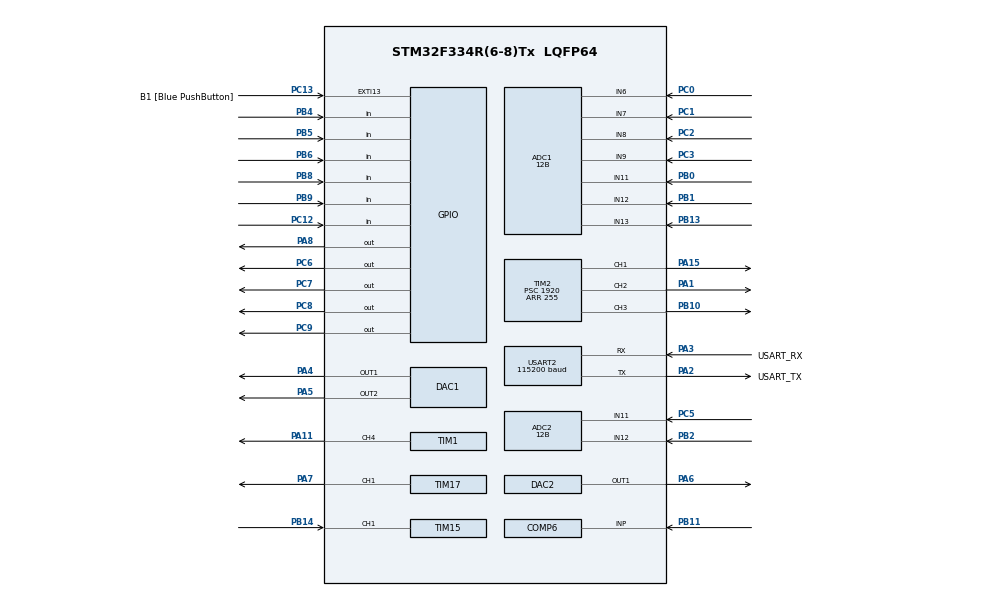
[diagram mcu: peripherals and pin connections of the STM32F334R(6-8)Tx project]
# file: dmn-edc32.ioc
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ADC1.Channel-11\#ChannelRegularConversion=ADC_CHANNEL_6
ADC1.Channel-12\#ChannelRegularConversion=ADC_CHANNEL_7
ADC1.Channel-13\#ChannelRegularConversion=ADC_CHANNEL_8
ADC1.Channel-14\#ChannelRegularConversion=ADC_CHANNEL_9
ADC1.Channel-15\#ChannelRegularConversion=ADC_CHANNEL_11
ADC1.Channel-16\#ChannelRegularConversion=ADC_CHANNEL_12
ADC1.Channel-17\#ChannelRegularConversion=ADC_CHANNEL_13
ADC1.Channel-18\#ChannelRegularConversion=ADC_CHANNEL_TEMPSENSOR
ADC1.ClockPrescaler=ADC_CLOCK_ASYNC_DIV1
ADC1.ContinuousConvMode=ENABLE
ADC1.DMAContinuousRequests=DISABLE
ADC1.DataAlign=ADC_DATAALIGN_RIGHT
ADC1.DiscontinuousConvMode=DISABLE
ADC1.EOCSelection=ADC_EOC_SINGLE_CONV
ADC1.EnableAnalogWatchDog1=false
ADC1.EnableAnalogWatchDog2=false
ADC1.EnableAnalogWatchDog3=false
ADC1.EnableInjectedConversion=ENABLE
ADC1.EnableRegularConversion=ENABLE
ADC1.ExternalTrigConv=ADC_SOFTWARE_START
ADC1.ExternalTrigConvEdge=ADC_EXTERNALTRIGCONVEDGE_NONE
ADC1.InjNumberOfConversion=0
ADC1.LowPowerAutoWait=DISABLE
ADC1.NbrOfConversion=8
ADC1.Offset-11\#ChannelRegularConversion=0
ADC1.Offset-12\#ChannelRegularConversion=0
ADC1.Offset-13\#ChannelRegularConversion=0
ADC1.Offset-14\#ChannelRegularConversion=0
ADC1.Offset-15\#ChannelRegularConversion=0
ADC1.Offset-16\#ChannelRegularConversion=0
ADC1.Offset-17\#ChannelRegularConversion=0
ADC1.Offset-18\#ChannelRegularConversion=0
ADC1.OffsetNumber-11\#ChannelRegularConversion=ADC_OFFSET_NONE
ADC1.OffsetNumber-12\#ChannelRegularConversion=ADC_OFFSET_NONE
ADC1.OffsetNumber-13\#ChannelRegularConversion=ADC_OFFSET_NONE
ADC1.OffsetNumber-14\#ChannelRegularConversion=ADC_OFFSET_NONE
ADC1.OffsetNumber-15\#ChannelRegularConversion=ADC_OFFSET_NONE
ADC1.OffsetNumber-16\#ChannelRegularConversion=ADC_OFFSET_NONE
ADC1.OffsetNumber-17\#ChannelRegularConversion=ADC_OFFSET_NONE
ADC1.OffsetNumber-18\#ChannelRegularConversion=ADC_OFFSET_NONE
ADC1.Overrun=ADC_OVR_DATA_OVERWRITTEN
ADC1.Rank-11\#ChannelRegularConversion=1
ADC1.Rank-12\#ChannelRegularConversion=2
ADC1.Rank-13\#ChannelRegularConversion=3
ADC1.Rank-14\#ChannelRegularConversion=4
ADC1.Rank-15\#ChannelRegularConversion=5
ADC1.Rank-16\#ChannelRegularConversion=6
ADC1.Rank-17\#ChannelRegularConversion=7
ADC1.Rank-18\#ChannelRegularConversion=8
ADC1.Resolution=ADC_RESOLUTION_12B
ADC1.SamplingTime-11\#ChannelRegularConversion=ADC_SAMPLETIME_61CYCLES_5
ADC1.SamplingTime-12\#ChannelRegularConversion=ADC_SAMPLETIME_61CYCLES_5
ADC1.SamplingTime-13\#ChannelRegularConversion=ADC_SAMPLETIME_61CYCLES_5
ADC1.SamplingTime-14\#ChannelRegularConversion=ADC_SAMPLETIME_61CYCLES_5
ADC1.SamplingTime-15\#ChannelRegularConversion=ADC_SAMPLETIME_61CYCLES_5
ADC1.SamplingTime-16\#ChannelRegularConversion=ADC_SAMPLETIME_61CYCLES_5
ADC1.SamplingTime-17\#ChannelRegularConversion=ADC_SAMPLETIME_61CYCLES_5
ADC1.SamplingTime-18\#ChannelRegularConversion=ADC_SAMPLETIME_7CYCLES_5
ADC1.ScanConvMode=ADC_SCAN_ENABLE
ADC1.SubFamily=STM32F334x8
ADC1.master=1
ADC2.Channel-0\#ChannelRegularConversion=ADC_CHANNEL_11
ADC2.ClockPrescaler=ADC_CLOCK_ASYNC_DIV1
ADC2.ContinuousConvMode=ENABLE
ADC2.DMAContinuousRequests=DISABLE
ADC2.DataAlign=ADC_DATAALIGN_RIGHT
ADC2.DiscontinuousConvMode=DISABLE
ADC2.EOCSelection=ADC_EOC_SINGLE_CONV
ADC2.EnableAnalogWatchDog1=false
ADC2.EnableAnalogWatchDog2=false
ADC2.EnableAnalogWatchDog3=false
ADC2.EnableInjectedConversion=ENABLE
ADC2.EnableRegularConversion=ENABLE
ADC2.ExternalTrigConv=ADC_SOFTWARE_START
ADC2.ExternalTrigConvEdge=ADC_EXTERNALTRIGCONVEDGE_NONE
ADC2.InjNumberOfConversion=0
ADC2.LowPowerAutoWait=DISABLE
ADC2.NbrOfConversion=1
ADC2.NbrOfConversionFlag=1
ADC2.Offset-0\#ChannelRegularConversion=0
ADC2.OffsetNumber-0\#ChannelRegularConversion=ADC_OFFSET_NONE
ADC2.Overrun=ADC_OVR_DATA_OVERWRITTEN
ADC2.Rank-0\#ChannelRegularConversion=1
ADC2.Resolution=ADC_RESOLUTION_12B
ADC2.SamplingTime-0\#ChannelRegularConversion=ADC_SAMPLETIME_61CYCLES_5
ADC2.ScanConvMode=ADC_SCAN_DISABLE
ADC2.SingleDiff-0\#ChannelRegularConversion=ADC_DIFFERENTIAL_ENDED
ADC2.SubFamily=STM32F334x8
COMP6.InvertingInput=COMP_INVERTINGINPUT_DAC2_CH1
COMP6.TriggerMode=COMP_TRIGGERMODE_IT_RISING
DAC1.DAC_Trigger=DAC_TRIGGER_T6_TRGO
DAC1.DAC_Trigger2=DAC_TRIGGER_T6_TRGO
Dma.ADC1.4.Direction=DMA_PERIPH_TO_MEMORY
Dma.ADC1.4.Instance=DMA1_Channel1
Dma.ADC1.4.MemDataAlignment=DMA_MDATAALIGN_HALFWORD
Dma.ADC1.4.MemInc=DMA_MINC_ENABLE
Dma.ADC1.4.Mode=DMA_CIRCULAR
Dma.ADC1.4.PeriphDataAlignment=DMA_PDATAALIGN_HALFWORD
Dma.ADC1.4.PeriphInc=DMA_PINC_DISABLE
Dma.ADC1.4.Priority=DMA_PRIORITY_LOW
Dma.ADC2.3.Direction=DMA_PERIPH_TO_MEMORY
Dma.ADC2.3.Instance=DMA1_Channel2
Dma.ADC2.3.MemDataAlignment=DMA_MDATAALIGN_HALFWORD
Dma.ADC2.3.MemInc=DMA_MINC_ENABLE
Dma.ADC2.3.Mode=DMA_NORMAL
Dma.ADC2.3.PeriphDataAlignment=DMA_PDATAALIGN_HALFWORD
Dma.ADC2.3.PeriphInc=DMA_PINC_DISABLE
Dma.ADC2.3.Priority=DMA_PRIORITY_LOW
Dma.DAC1_CH1.1.Direction=DMA_MEMORY_TO_PERIPH
Dma.DAC1_CH1.1.Instance=DMA1_Channel3
Dma.DAC1_CH1.1.MemDataAlignment=DMA_MDATAALIGN_HALFWORD
Dma.DAC1_CH1.1.MemInc=DMA_MINC_ENABLE
Dma.DAC1_CH1.1.Mode=DMA_CIRCULAR
Dma.DAC1_CH1.1.PeriphDataAlignment=DMA_PDATAALIGN_HALFWORD
Dma.DAC1_CH1.1.PeriphInc=DMA_PINC_DISABLE
Dma.DAC1_CH1.1.Priority=DMA_PRIORITY_VERY_HIGH
Dma.DAC1_CH2.2.Direction=DMA_MEMORY_TO_PERIPH
Dma.DAC1_CH2.2.Instance=DMA1_Channel4
Dma.DAC1_CH2.2.MemDataAlignment=DMA_MDATAALIGN_HALFWORD
Dma.DAC1_CH2.2.MemInc=DMA_MINC_ENABLE
Dma.DAC1_CH2.2.Mode=DMA_CIRCULAR
Dma.DAC1_CH2.2.PeriphDataAlignment=DMA_PDATAALIGN_HALFWORD
Dma.DAC1_CH2.2.PeriphInc=DMA_PINC_DISABLE
Dma.DAC1_CH2.2.Priority=DMA_PRIORITY_VERY_HIGH
Dma.Request0=USART2_RX
Dma.Request1=DAC1_CH1
Dma.Request2=DAC1_CH2
Dma.Request3=ADC2
Dma.Request4=ADC1
Dma.USART2_RX.0.Direction=DMA_PERIPH_TO_MEMORY
Dma.USART2_RX.0.Instance=DMA1_Channel6
Dma.USART2_RX.0.MemDataAlignment=DMA_MDATAALIGN_BYTE
Dma.USART2_RX.0.MemInc=DMA_MINC_ENABLE
Dma.USART2_RX.0.Mode=DMA_CIRCULAR
Dma.USART2_RX.0.PeriphDataAlignment=DMA_PDATAALIGN_BYTE
Dma.USART2_RX.0.PeriphInc=DMA_PINC_DISABLE
Dma.USART2_RX.0.Priority=DMA_PRIORITY_LOW
Mcu.Family=STM32F3
Mcu.Name=STM32F334R(6-8)Tx
Mcu.Package=LQFP64
NVIC.ADC1_2_IRQn=true\:0\:0\:false\:false\:true\:true\:true\:true
NVIC.COMP4_6_IRQn=true\:0\:0\:false\:false\:true\:true\:true\:true
NVIC.DMA1_Channel1_IRQn=true\:0\:0\:false\:false\:true\:true\:true\:true
NVIC.DMA1_Channel2_IRQn=true\:0\:0\:false\:false\:true\:true\:true\:true
NVIC.DMA1_Channel3_IRQn=true\:0\:0\:false\:false\:true\:true\:true\:true
NVIC.DMA1_Channel4_IRQn=true\:0\:0\:false\:false\:true\:true\:true\:true
NVIC.DMA1_Channel6_IRQn=true\:0\:0\:false\:false\:true\:true\:true\:true
NVIC.PriorityGroup=NVIC_PRIORITYGROUP_4
NVIC.TIM1_BRK_TIM15_IRQn=true\:0\:0\:false\:false\:true\:true\:true\:true
NVIC.TIM7_DAC2_IRQn=true\:0\:0\:false\:false\:true\:true\:true\:true
NVIC.TimeBase=TIM7_DAC2_IRQn
NVIC.TimeBaseIP=TIM7
NVIC.USART2_IRQn=true\:0\:0\:false\:false\:true\:true\:true\:true
PA1.Signal=S_TIM2_CH2
PA11.Signal=S_TIM1_CH4
PA13.GPIO_Label=TMS
PA13.Signal=SYS_JTMS-SWDIO
PA14.GPIO_Label=TCK
PA14.Signal=SYS_JTCK-SWCLK
PA15.Signal=S_TIM2_CH1_ETR
PA2.GPIO_Label=USART_TX
PA2.Mode=Asynchronous
PA2.Signal=USART2_TX
PA3.GPIO_Label=USART_RX
PA3.Mode=Asynchronous
PA3.Signal=USART2_RX
PA4.Signal=COMP_DAC11_group
PA5.Signal=COMP_DAC12_group
PA6.Signal=COMP_DAC21_group
PA7.Signal=S_TIM17_CH1
PA8.Signal=GPIO_Output
PB0.Mode=IN11-Single-Ended
PB0.Signal=ADC1_IN11
PB1.Mode=IN12-Single-Ended
PB1.Signal=ADC1_IN12
PB10.Signal=S_TIM2_CH3
PB11.GPIO_PuPd=GPIO_NOPULL
PB11.Mode=INP
PB11.Signal=COMP6_INP
PB13.Mode=IN13-Single-Ended
PB13.Signal=ADC1_IN13
PB14.GPIO_PuPd=GPIO_PULLUP
PB14.Signal=S_TIM15_CH1
PB2.Mode=IN11-Differential
PB2.Signal=ADC2_IN12
PB3.GPIO_Label=SWO
PB3.Signal=SYS_JTDO-TRACESWO
PB4.Signal=GPIO_Input
PB5.Signal=GPIO_Input
PB6.Signal=GPIO_Input
PB8.Signal=GPIO_Input
PB9.Signal=GPIO_Input
PC0.Signal=ADCx_IN6
PC1.Signal=ADCx_IN7
PC12.Signal=GPIO_Input
PC13.GPIO_Label=B1 [Blue PushButton]
PC13.GPIO_ModeDefaultEXTI=GPIO_MODE_IT_FALLING
PC13.Signal=GPXTI13
PC14\ /\ OSC32_IN.Signal=RCC_OSC32_IN
PC15\ /\ OSC32_OUT.GPIO_Label=RCC_OSC32_OUT
PC15\ /\ OSC32_OUT.Signal=RCC_OSC32_OUT
PC2.Signal=ADCx_IN8
PC3.Signal=ADCx_IN9
PC5.Mode=IN11-Differential
PC5.Signal=ADC2_IN11
PC6.Signal=GPIO_Output
PC7.Signal=GPIO_Output
PC8.Signal=GPIO_Output
PC9.Signal=GPIO_Output
PF0\ /\ OSC_IN.Signal=RCC_OSC_IN
PF1\ /\ OSC_OUT.Signal=RCC_OSC_OUT
ProjectManager.HeapSize=0x200
ProjectManager.StackSize=0x400
ProjectManager.TargetToolchain=Makefile
RCC.AHBFreq_Value=64000000
RCC.APB1CLKDivider=RCC_HCLK_DIV2
RCC.APB1Freq_Value=32000000
RCC.APB1TimFreq_Value=64000000
RCC.APB2Freq_Value=64000000
RCC.APB2TimFreq_Value=64000000
RCC.CortexFreq_Value=64000000
RCC.FLatency-AdvancedSettings=FLASH_LATENCY_2
RCC.HCLKFreq_Value=64000000
RCC.HSE_VALUE=8000000
RCC.HSI_VALUE=8000000
RCC.LSE_VALUE=32768
RCC.PLLMUL=RCC_PLL_MUL16
RCC.SYSCLKFreq_VALUE=64000000
RCC.SYSCLKSourceVirtual=RCC_SYSCLKSOURCE_PLLCLK
SH.ADCx_IN6.0=ADC1_IN6,IN6-Single-Ended
SH.ADCx_IN7.0=ADC1_IN7,IN7-Single-Ended
SH.ADCx_IN8.0=ADC1_IN8,IN8-Single-Ended
SH.ADCx_IN9.0=ADC1_IN9,IN9-Single-Ended
SH.COMP_DAC11_group.0=DAC1_OUT1,DAC_OUT1
SH.COMP_DAC12_group.0=DAC1_OUT2,DAC_OUT2
SH.COMP_DAC21_group.0=DAC2_OUT1,Switch_Enable_OUT1
SH.S_TIM15_CH1.0=TIM15_CH1,Input_Capture1_from_TI1
SH.S_TIM17_CH1.0=TIM17_CH1,PWM Generation1 CH1
SH.S_TIM1_CH4.0=TIM1_CH4,PWM Generation4 CH4
SH.S_TIM2_CH1_ETR.0=TIM2_CH1,PWM Generation1 CH1
SH.S_TIM2_CH2.0=TIM2_CH2,PWM Generation2 CH2
SH.S_TIM2_CH3.0=TIM2_CH3,PWM Generation3 CH3
TIM1.AutoReloadPreload=TIM_AUTORELOAD_PRELOAD_ENABLE
TIM1.Channel-PWM\ Generation4\ CH4=TIM_CHANNEL_4
TIM1.Period=4095
TIM1.Prescaler=31
TIM15.Channel-Input_Capture1_from_TI1=TIM_CHANNEL_1
TIM15.ICFilter_CH1=15
TIM15.Period=65535
TIM15.Prescaler=244
TIM17.Channel=TIM_CHANNEL_1
TIM17.Period=65535
TIM17.Prescaler=976
TIM17.Pulse=10000
TIM2.Channel-PWM\ Generation1\ CH1=TIM_CHANNEL_1
TIM2.Channel-PWM\ Generation2\ CH2=TIM_CHANNEL_2
TIM2.Channel-PWM\ Generation3\ CH3=TIM_CHANNEL_3
TIM2.Period=255
TIM2.Prescaler=1920
TIM6.Period=49
TIM6.TIM_MasterOutputTrigger=TIM_TRGO_UPDATE
USART2.BaudRate=115200
USART2.VirtualMode-Asynchronous=VM_ASYNC
USART2.WordLength=WORDLENGTH_8B
VP_ADC1_TempSens_Input.Mode=IN-TempSens
VP_COMP6_VS_DAC2OUT1.Mode=INM_DAC2OUT1
VP_SYS_VS_tim7.Mode=TIM7
VP_TIM15_VS_ClockSourceINT.Mode=Internal
VP_TIM17_VS_ClockSourceINT.Mode=Enable_Timer
VP_TIM1_VS_ClockSourceINT.Mode=Internal
VP_TIM2_VS_ClockSourceINT.Mode=Internal
VP_TIM3_VS_ClockSourceINT.Mode=Internal
VP_TIM6_VS_ClockSourceINT.Mode=Enable_Timer
board=NUCLEO-F334R8

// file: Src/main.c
/* USER CODE BEGIN Header */
/**
  ******************************************************************************
  * @file           : main.c
  * @brief          : Main program body
  ******************************************************************************
  * @attention
  *
  * Copyright (c) 2022 STMicroelectronics.
  * All rights reserved.
  *
  * This software is licensed under terms that can be found in the LICENSE file
  * in the root directory of this software component.
  * If no LICENSE file comes with this software, it is provided AS-IS.
  *
  ******************************************************************************
  */
/* USER CODE END Header */
#include "main.h"

/* USER CODE BEGIN Includes */
#include "edc/edcmain.h"

/* USER CODE END Includes */

void SystemClock_Config(void);
static void MX_GPIO_Init(void);
static void MX_DMA_Init(void);
static void MX_USART2_UART_Init(void);
static void MX_DAC1_Init(void);
static void MX_DAC2_Init(void);
static void MX_TIM2_Init(void);
static void MX_COMP6_Init(void);
static void MX_ADC2_Init(void);
static void MX_TIM1_Init(void);
static void MX_ADC1_Init(void);
static void MX_TIM3_Init(void);
static void MX_TIM17_Init(void);
static void MX_TIM15_Init(void);
static void MX_TIM6_Init(void);

int main(void)
{

  /* MCU Configuration--------------------------------------------------------*/

  /* Reset of all peripherals, Initializes the Flash interface and the Systick. */
  HAL_Init();

  /* Configure the system clock */
  SystemClock_Config();

  /* Initialize all configured peripherals */
  MX_GPIO_Init();
  MX_DMA_Init();
  MX_USART2_UART_Init();
  MX_DAC1_Init();
  MX_DAC2_Init();
  MX_TIM2_Init();
  MX_COMP6_Init();
  MX_ADC2_Init();
  MX_TIM1_Init();
  MX_ADC1_Init();
  MX_TIM3_Init();
  MX_TIM17_Init();
  MX_TIM15_Init();
  MX_TIM6_Init();
  /* USER CODE BEGIN 2 */

  edcmain();
  /* USER CODE END 2 */

  /* Infinite loop */
  while (1)
  {

  }
}

void SystemClock_Config(void)
{
  LL_FLASH_SetLatency(LL_FLASH_LATENCY_2);
  while(LL_FLASH_GetLatency()!= LL_FLASH_LATENCY_2)
  {
  }
  LL_RCC_HSI_Enable();

   /* Wait till HSI is ready */
  while(LL_RCC_HSI_IsReady() != 1)
  {

  }
  LL_RCC_HSI_SetCalibTrimming(16);
  LL_RCC_PLL_ConfigDomain_SYS(LL_RCC_PLLSOURCE_HSI_DIV_2, LL_RCC_PLL_MUL_16);
  LL_RCC_PLL_Enable();

   /* Wait till PLL is ready */
  while(LL_RCC_PLL_IsReady() != 1)
  {

  }
  LL_RCC_SetAHBPrescaler(LL_RCC_SYSCLK_DIV_1);
  LL_RCC_SetAPB1Prescaler(LL_RCC_APB1_DIV_2);
  LL_RCC_SetAPB2Prescaler(LL_RCC_APB2_DIV_1);
  LL_RCC_SetSysClkSource(LL_RCC_SYS_CLKSOURCE_PLL);

   /* Wait till System clock is ready */
  while(LL_RCC_GetSysClkSource() != LL_RCC_SYS_CLKSOURCE_STATUS_PLL)
  {

  }
  LL_SetSystemCoreClock(64000000);

   /* Update the time base */
  if (HAL_InitTick (TICK_INT_PRIORITY) != HAL_OK)
  {
    Error_Handler();
  }
  LL_RCC_SetTIMClockSource(LL_RCC_TIM1_CLKSOURCE_PCLK2);
  LL_RCC_SetADCClockSource(LL_RCC_ADC12_CLKSRC_PLL_DIV_1);
}

static void MX_ADC1_Init(void)
{

  LL_ADC_InitTypeDef ADC_InitStruct = {0};
  LL_ADC_REG_InitTypeDef ADC_REG_InitStruct = {0};
  LL_ADC_CommonInitTypeDef ADC_CommonInitStruct = {0};

  LL_GPIO_InitTypeDef GPIO_InitStruct = {0};

  /* Peripheral clock enable */
  LL_AHB1_GRP1_EnableClock(LL_AHB1_GRP1_PERIPH_ADC12);

  LL_AHB1_GRP1_EnableClock(LL_AHB1_GRP1_PERIPH_GPIOC);
  LL_AHB1_GRP1_EnableClock(LL_AHB1_GRP1_PERIPH_GPIOB);
  /**ADC1 GPIO Configuration
  PC0   ------> ADC1_IN6
  PC1   ------> ADC1_IN7
  PC2   ------> ADC1_IN8
  PC3   ------> ADC1_IN9
  PB0   ------> ADC1_IN11
  PB1   ------> ADC1_IN12
  PB13   ------> ADC1_IN13
  */
  GPIO_InitStruct.Pin = LL_GPIO_PIN_0|LL_GPIO_PIN_1|LL_GPIO_PIN_2|LL_GPIO_PIN_3;
  GPIO_InitStruct.Mode = LL_GPIO_MODE_ANALOG;
  GPIO_InitStruct.Pull = LL_GPIO_PULL_NO;
  LL_GPIO_Init(GPIOC, &GPIO_InitStruct);

  GPIO_InitStruct.Pin = LL_GPIO_PIN_0|LL_GPIO_PIN_1|LL_GPIO_PIN_13;
  GPIO_InitStruct.Mode = LL_GPIO_MODE_ANALOG;
  GPIO_InitStruct.Pull = LL_GPIO_PULL_NO;
  LL_GPIO_Init(GPIOB, &GPIO_InitStruct);

  /* ADC1 DMA Init */

  /* ADC1 Init */
  LL_DMA_SetDataTransferDirection(DMA1, LL_DMA_CHANNEL_1, LL_DMA_DIRECTION_PERIPH_TO_MEMORY);

  LL_DMA_SetChannelPriorityLevel(DMA1, LL_DMA_CHANNEL_1, LL_DMA_PRIORITY_LOW);

  LL_DMA_SetMode(DMA1, LL_DMA_CHANNEL_1, LL_DMA_MODE_CIRCULAR);

  LL_DMA_SetPeriphIncMode(DMA1, LL_DMA_CHANNEL_1, LL_DMA_PERIPH_NOINCREMENT);

  LL_DMA_SetMemoryIncMode(DMA1, LL_DMA_CHANNEL_1, LL_DMA_MEMORY_INCREMENT);

  LL_DMA_SetPeriphSize(DMA1, LL_DMA_CHANNEL_1, LL_DMA_PDATAALIGN_HALFWORD);

  LL_DMA_SetMemorySize(DMA1, LL_DMA_CHANNEL_1, LL_DMA_MDATAALIGN_HALFWORD);

  /* ADC1 interrupt Init */
  NVIC_SetPriority(ADC1_2_IRQn, NVIC_EncodePriority(NVIC_GetPriorityGrouping(),0, 0));
  NVIC_EnableIRQ(ADC1_2_IRQn);

  /** Common config
  */
  ADC_InitStruct.Resolution = LL_ADC_RESOLUTION_12B;
  ADC_InitStruct.DataAlignment = LL_ADC_DATA_ALIGN_RIGHT;
  ADC_InitStruct.LowPowerMode = LL_ADC_LP_MODE_NONE;
  LL_ADC_Init(ADC1, &ADC_InitStruct);
  ADC_REG_InitStruct.TriggerSource = LL_ADC_REG_TRIG_SOFTWARE;
  ADC_REG_InitStruct.SequencerLength = LL_ADC_REG_SEQ_SCAN_ENABLE_8RANKS;
  ADC_REG_InitStruct.SequencerDiscont = LL_ADC_REG_SEQ_DISCONT_DISABLE;
  ADC_REG_InitStruct.ContinuousMode = LL_ADC_REG_CONV_CONTINUOUS;
  ADC_REG_InitStruct.DMATransfer = LL_ADC_REG_DMA_TRANSFER_LIMITED;
  ADC_REG_InitStruct.Overrun = LL_ADC_REG_OVR_DATA_OVERWRITTEN;
  LL_ADC_REG_Init(ADC1, &ADC_REG_InitStruct);
  ADC_CommonInitStruct.CommonClock = LL_ADC_CLOCK_ASYNC_DIV1;
  ADC_CommonInitStruct.Multimode = LL_ADC_MULTI_INDEPENDENT;
  LL_ADC_CommonInit(__LL_ADC_COMMON_INSTANCE(ADC1), &ADC_CommonInitStruct);

  /* Enable ADC internal voltage regulator */
  LL_ADC_EnableInternalRegulator(ADC1);
  /* Delay for ADC internal voltage regulator stabilization. */
  /* Compute number of CPU cycles to wait for, from delay in us. */
  /* Note: Variable divided by 2 to compensate partially */
  /* CPU processing cycles (depends on compilation optimization). */
  /* Note: If system core clock frequency is below 200kHz, wait time */
  /* is only a few CPU processing cycles. */
  uint32_t wait_loop_index;
  wait_loop_index = ((LL_ADC_DELAY_INTERNAL_REGUL_STAB_US * (SystemCoreClock / (100000 * 2))) / 10);
  while(wait_loop_index != 0)
  {
    wait_loop_index--;
  }

  /** Configure Regular Channel
  */
  LL_ADC_REG_SetSequencerRanks(ADC1, LL_ADC_REG_RANK_1, LL_ADC_CHANNEL_6);
  LL_ADC_SetChannelSamplingTime(ADC1, LL_ADC_CHANNEL_6, LL_ADC_SAMPLINGTIME_61CYCLES_5);
  LL_ADC_SetChannelSingleDiff(ADC1, LL_ADC_CHANNEL_6, LL_ADC_SINGLE_ENDED);

  /** Configure Regular Channel
  */
  LL_ADC_REG_SetSequencerRanks(ADC1, LL_ADC_REG_RANK_2, LL_ADC_CHANNEL_7);
  LL_ADC_SetChannelSamplingTime(ADC1, LL_ADC_CHANNEL_7, LL_ADC_SAMPLINGTIME_61CYCLES_5);
  LL_ADC_SetChannelSingleDiff(ADC1, LL_ADC_CHANNEL_7, LL_ADC_SINGLE_ENDED);

  /** Configure Regular Channel
  */
  LL_ADC_REG_SetSequencerRanks(ADC1, LL_ADC_REG_RANK_3, LL_ADC_CHANNEL_8);
  LL_ADC_SetChannelSamplingTime(ADC1, LL_ADC_CHANNEL_8, LL_ADC_SAMPLINGTIME_61CYCLES_5);
  LL_ADC_SetChannelSingleDiff(ADC1, LL_ADC_CHANNEL_8, LL_ADC_SINGLE_ENDED);

  /** Configure Regular Channel
  */
  LL_ADC_REG_SetSequencerRanks(ADC1, LL_ADC_REG_RANK_4, LL_ADC_CHANNEL_9);
  LL_ADC_SetChannelSamplingTime(ADC1, LL_ADC_CHANNEL_9, LL_ADC_SAMPLINGTIME_61CYCLES_5);
  LL_ADC_SetChannelSingleDiff(ADC1, LL_ADC_CHANNEL_9, LL_ADC_SINGLE_ENDED);

  /** Configure Regular Channel
  */
  LL_ADC_REG_SetSequencerRanks(ADC1, LL_ADC_REG_RANK_5, LL_ADC_CHANNEL_11);
  LL_ADC_SetChannelSamplingTime(ADC1, LL_ADC_CHANNEL_11, LL_ADC_SAMPLINGTIME_61CYCLES_5);
  LL_ADC_SetChannelSingleDiff(ADC1, LL_ADC_CHANNEL_11, LL_ADC_SINGLE_ENDED);

  /** Configure Regular Channel
  */
  LL_ADC_REG_SetSequencerRanks(ADC1, LL_ADC_REG_RANK_6, LL_ADC_CHANNEL_12);
  LL_ADC_SetChannelSamplingTime(ADC1, LL_ADC_CHANNEL_12, LL_ADC_SAMPLINGTIME_61CYCLES_5);
  LL_ADC_SetChannelSingleDiff(ADC1, LL_ADC_CHANNEL_12, LL_ADC_SINGLE_ENDED);

  /** Configure Regular Channel
  */
  LL_ADC_REG_SetSequencerRanks(ADC1, LL_ADC_REG_RANK_7, LL_ADC_CHANNEL_13);
  LL_ADC_SetChannelSamplingTime(ADC1, LL_ADC_CHANNEL_13, LL_ADC_SAMPLINGTIME_61CYCLES_5);
  LL_ADC_SetChannelSingleDiff(ADC1, LL_ADC_CHANNEL_13, LL_ADC_SINGLE_ENDED);

  /** Configure Regular Channel
  */
  LL_ADC_REG_SetSequencerRanks(ADC1, LL_ADC_REG_RANK_8, LL_ADC_CHANNEL_TEMPSENSOR);
  LL_ADC_SetChannelSamplingTime(ADC1, LL_ADC_CHANNEL_TEMPSENSOR, LL_ADC_SAMPLINGTIME_7CYCLES_5);
  LL_ADC_SetChannelSingleDiff(ADC1, LL_ADC_CHANNEL_TEMPSENSOR, LL_ADC_SINGLE_ENDED);
  LL_ADC_SetCommonPathInternalCh(__LL_ADC_COMMON_INSTANCE(ADC1), LL_ADC_PATH_INTERNAL_TEMPSENSOR);

}

static void MX_ADC2_Init(void)
{

  LL_ADC_InitTypeDef ADC_InitStruct = {0};
  LL_ADC_REG_InitTypeDef ADC_REG_InitStruct = {0};

  LL_GPIO_InitTypeDef GPIO_InitStruct = {0};

  /* Peripheral clock enable */
  LL_AHB1_GRP1_EnableClock(LL_AHB1_GRP1_PERIPH_ADC12);

  LL_AHB1_GRP1_EnableClock(LL_AHB1_GRP1_PERIPH_GPIOC);
  LL_AHB1_GRP1_EnableClock(LL_AHB1_GRP1_PERIPH_GPIOB);
  /**ADC2 GPIO Configuration
  PC5   ------> ADC2_IN11
  PB2   ------> ADC2_IN12
  */
  GPIO_InitStruct.Pin = LL_GPIO_PIN_5;
  GPIO_InitStruct.Mode = LL_GPIO_MODE_ANALOG;
  GPIO_InitStruct.Pull = LL_GPIO_PULL_NO;
  LL_GPIO_Init(GPIOC, &GPIO_InitStruct);

  GPIO_InitStruct.Pin = LL_GPIO_PIN_2;
  GPIO_InitStruct.Mode = LL_GPIO_MODE_ANALOG;
  GPIO_InitStruct.Pull = LL_GPIO_PULL_NO;
  LL_GPIO_Init(GPIOB, &GPIO_InitStruct);

  /* ADC2 DMA Init */

  /* ADC2 Init */
  LL_DMA_SetDataTransferDirection(DMA1, LL_DMA_CHANNEL_2, LL_DMA_DIRECTION_PERIPH_TO_MEMORY);

  LL_DMA_SetChannelPriorityLevel(DMA1, LL_DMA_CHANNEL_2, LL_DMA_PRIORITY_LOW);

  LL_DMA_SetMode(DMA1, LL_DMA_CHANNEL_2, LL_DMA_MODE_NORMAL);

  LL_DMA_SetPeriphIncMode(DMA1, LL_DMA_CHANNEL_2, LL_DMA_PERIPH_NOINCREMENT);

  LL_DMA_SetMemoryIncMode(DMA1, LL_DMA_CHANNEL_2, LL_DMA_MEMORY_INCREMENT);

  LL_DMA_SetPeriphSize(DMA1, LL_DMA_CHANNEL_2, LL_DMA_PDATAALIGN_HALFWORD);

  LL_DMA_SetMemorySize(DMA1, LL_DMA_CHANNEL_2, LL_DMA_MDATAALIGN_HALFWORD);

  /* ADC2 interrupt Init */
  NVIC_SetPriority(ADC1_2_IRQn, NVIC_EncodePriority(NVIC_GetPriorityGrouping(),0, 0));
  NVIC_EnableIRQ(ADC1_2_IRQn);

  /** Common config
  */
  ADC_InitStruct.Resolution = LL_ADC_RESOLUTION_12B;
  ADC_InitStruct.DataAlignment = LL_ADC_DATA_ALIGN_RIGHT;
  ADC_InitStruct.LowPowerMode = LL_ADC_LP_MODE_NONE;
  LL_ADC_Init(ADC2, &ADC_InitStruct);
  ADC_REG_InitStruct.TriggerSource = LL_ADC_REG_TRIG_SOFTWARE;
  ADC_REG_InitStruct.SequencerLength = LL_ADC_REG_SEQ_SCAN_DISABLE;
  ADC_REG_InitStruct.SequencerDiscont = LL_ADC_REG_SEQ_DISCONT_DISABLE;
  ADC_REG_InitStruct.ContinuousMode = LL_ADC_REG_CONV_CONTINUOUS;
  ADC_REG_InitStruct.DMATransfer = LL_ADC_REG_DMA_TRANSFER_LIMITED;
  ADC_REG_InitStruct.Overrun = LL_ADC_REG_OVR_DATA_OVERWRITTEN;
  LL_ADC_REG_Init(ADC2, &ADC_REG_InitStruct);

  /* Enable ADC internal voltage regulator */
  LL_ADC_EnableInternalRegulator(ADC2);
  /* Delay for ADC internal voltage regulator stabilization. */
  /* Compute number of CPU cycles to wait for, from delay in us. */
  /* Note: Variable divided by 2 to compensate partially */
  /* CPU processing cycles (depends on compilation optimization). */
  /* Note: If system core clock frequency is below 200kHz, wait time */
  /* is only a few CPU processing cycles. */
  uint32_t wait_loop_index;
  wait_loop_index = ((LL_ADC_DELAY_INTERNAL_REGUL_STAB_US * (SystemCoreClock / (100000 * 2))) / 10);
  while(wait_loop_index != 0)
  {
    wait_loop_index--;
  }

  /** Configure Regular Channel
  */
  LL_ADC_REG_SetSequencerRanks(ADC2, LL_ADC_REG_RANK_1, LL_ADC_CHANNEL_11);
  LL_ADC_SetChannelSamplingTime(ADC2, LL_ADC_CHANNEL_11, LL_ADC_SAMPLINGTIME_61CYCLES_5);
  LL_ADC_SetChannelSingleDiff(ADC2, LL_ADC_CHANNEL_11, LL_ADC_DIFFERENTIAL_ENDED);

}

static void MX_COMP6_Init(void)
{

  LL_COMP_InitTypeDef COMP_InitStruct = {0};

  LL_GPIO_InitTypeDef GPIO_InitStruct = {0};

  LL_AHB1_GRP1_EnableClock(LL_AHB1_GRP1_PERIPH_GPIOB);
  /**COMP6 GPIO Configuration
  PB11   ------> COMP6_INP
  */
  GPIO_InitStruct.Pin = LL_GPIO_PIN_11;
  GPIO_InitStruct.Mode = LL_GPIO_MODE_ANALOG;
  GPIO_InitStruct.Pull = LL_GPIO_PULL_NO;
  LL_GPIO_Init(GPIOB, &GPIO_InitStruct);

  /* COMP6 interrupt Init */
  NVIC_SetPriority(COMP4_6_IRQn, NVIC_EncodePriority(NVIC_GetPriorityGrouping(),0, 0));
  NVIC_EnableIRQ(COMP4_6_IRQn);

  COMP_InitStruct.InputPlus = LL_COMP_INPUT_PLUS_IO1;
  COMP_InitStruct.InputMinus = LL_COMP_INPUT_MINUS_DAC2_CH1;
  COMP_InitStruct.OutputSelection = LL_COMP_OUTPUT_NONE;
  COMP_InitStruct.OutputPolarity = LL_COMP_OUTPUTPOL_NONINVERTED;
  COMP_InitStruct.OutputBlankingSource = LL_COMP_BLANKINGSRC_NONE;
  LL_COMP_Init(COMP6, &COMP_InitStruct);

}

static void MX_DAC1_Init(void)
{

  LL_DAC_InitTypeDef DAC_InitStruct = {0};

  LL_GPIO_InitTypeDef GPIO_InitStruct = {0};

  /* Peripheral clock enable */
  LL_APB1_GRP1_EnableClock(LL_APB1_GRP1_PERIPH_DAC1);

  LL_AHB1_GRP1_EnableClock(LL_AHB1_GRP1_PERIPH_GPIOA);
  /**DAC1 GPIO Configuration
  PA4   ------> DAC1_OUT1
  PA5   ------> DAC1_OUT2
  */
  GPIO_InitStruct.Pin = LL_GPIO_PIN_4|LL_GPIO_PIN_5;
  GPIO_InitStruct.Mode = LL_GPIO_MODE_ANALOG;
  GPIO_InitStruct.Pull = LL_GPIO_PULL_NO;
  LL_GPIO_Init(GPIOA, &GPIO_InitStruct);

  /* DAC1 DMA Init */

  /* DAC1_CH1 Init */
  LL_DMA_SetDataTransferDirection(DMA1, LL_DMA_CHANNEL_3, LL_DMA_DIRECTION_MEMORY_TO_PERIPH);

  LL_DMA_SetChannelPriorityLevel(DMA1, LL_DMA_CHANNEL_3, LL_DMA_PRIORITY_VERYHIGH);

  LL_DMA_SetMode(DMA1, LL_DMA_CHANNEL_3, LL_DMA_MODE_CIRCULAR);

  LL_DMA_SetPeriphIncMode(DMA1, LL_DMA_CHANNEL_3, LL_DMA_PERIPH_NOINCREMENT);

  LL_DMA_SetMemoryIncMode(DMA1, LL_DMA_CHANNEL_3, LL_DMA_MEMORY_INCREMENT);

  LL_DMA_SetPeriphSize(DMA1, LL_DMA_CHANNEL_3, LL_DMA_PDATAALIGN_HALFWORD);

  LL_DMA_SetMemorySize(DMA1, LL_DMA_CHANNEL_3, LL_DMA_MDATAALIGN_HALFWORD);

  LL_SYSCFG_SetRemapDMA_DAC(LL_SYSCFG_DAC1_CH1_RMP_DMA1_CH3);

  /* DAC1_CH2 Init */
  LL_DMA_SetDataTransferDirection(DMA1, LL_DMA_CHANNEL_4, LL_DMA_DIRECTION_MEMORY_TO_PERIPH);

  LL_DMA_SetChannelPriorityLevel(DMA1, LL_DMA_CHANNEL_4, LL_DMA_PRIORITY_VERYHIGH);

  LL_DMA_SetMode(DMA1, LL_DMA_CHANNEL_4, LL_DMA_MODE_CIRCULAR);

  LL_DMA_SetPeriphIncMode(DMA1, LL_DMA_CHANNEL_4, LL_DMA_PERIPH_NOINCREMENT);

  LL_DMA_SetMemoryIncMode(DMA1, LL_DMA_CHANNEL_4, LL_DMA_MEMORY_INCREMENT);

  LL_DMA_SetPeriphSize(DMA1, LL_DMA_CHANNEL_4, LL_DMA_PDATAALIGN_HALFWORD);

  LL_DMA_SetMemorySize(DMA1, LL_DMA_CHANNEL_4, LL_DMA_MDATAALIGN_HALFWORD);

  LL_SYSCFG_SetRemapDMA_DAC(LL_SYSCFG_DAC1_OUT2_RMP_DMA1_CH4);

  /** DAC channel OUT1 config
  */
  DAC_InitStruct.TriggerSource = LL_DAC_TRIG_EXT_TIM6_TRGO;
  DAC_InitStruct.WaveAutoGeneration = LL_DAC_WAVE_AUTO_GENERATION_NONE;
  DAC_InitStruct.OutputBuffer = LL_DAC_OUTPUT_BUFFER_ENABLE;
  LL_DAC_Init(DAC1, LL_DAC_CHANNEL_1, &DAC_InitStruct);
  LL_DAC_EnableTrigger(DAC1, LL_DAC_CHANNEL_1);

  /** DAC channel OUT2 config
  */
  DAC_InitStruct.OutputBuffer = LL_DAC_OUTPUT_SWITCH_ENABLE;
  LL_DAC_Init(DAC1, LL_DAC_CHANNEL_2, &DAC_InitStruct);
  LL_DAC_EnableTrigger(DAC1, LL_DAC_CHANNEL_2);

}

static void MX_DAC2_Init(void)
{

  LL_DAC_InitTypeDef DAC_InitStruct = {0};

  LL_GPIO_InitTypeDef GPIO_InitStruct = {0};

  /* Peripheral clock enable */
  LL_APB1_GRP1_EnableClock(LL_APB1_GRP1_PERIPH_DAC2);

  LL_AHB1_GRP1_EnableClock(LL_AHB1_GRP1_PERIPH_GPIOA);
  /**DAC2 GPIO Configuration
  PA6   ------> DAC2_OUT1
  */
  GPIO_InitStruct.Pin = LL_GPIO_PIN_6;
  GPIO_InitStruct.Mode = LL_GPIO_MODE_ANALOG;
  GPIO_InitStruct.Pull = LL_GPIO_PULL_NO;
  LL_GPIO_Init(GPIOA, &GPIO_InitStruct);

  /* DAC2 interrupt Init */
  NVIC_SetPriority(TIM7_DAC2_IRQn, NVIC_EncodePriority(NVIC_GetPriorityGrouping(),0, 0));
  NVIC_EnableIRQ(TIM7_DAC2_IRQn);

  /** DAC channel OUT1 config
  */
  DAC_InitStruct.TriggerSource = LL_DAC_TRIG_SOFTWARE;
  DAC_InitStruct.WaveAutoGeneration = LL_DAC_WAVE_AUTO_GENERATION_NONE;
  DAC_InitStruct.OutputBuffer = LL_DAC_OUTPUT_SWITCH_ENABLE;
  LL_DAC_Init(DAC2, LL_DAC_CHANNEL_1, &DAC_InitStruct);
  LL_DAC_DisableTrigger(DAC2, LL_DAC_CHANNEL_1);

}

static void MX_TIM1_Init(void)
{

  LL_TIM_InitTypeDef TIM_InitStruct = {0};
  LL_TIM_OC_InitTypeDef TIM_OC_InitStruct = {0};
  LL_TIM_BDTR_InitTypeDef TIM_BDTRInitStruct = {0};

  LL_GPIO_InitTypeDef GPIO_InitStruct = {0};

  /* Peripheral clock enable */
  LL_APB2_GRP1_EnableClock(LL_APB2_GRP1_PERIPH_TIM1);

  /* TIM1 interrupt Init */
  NVIC_SetPriority(TIM1_BRK_TIM15_IRQn, NVIC_EncodePriority(NVIC_GetPriorityGrouping(),0, 0));
  NVIC_EnableIRQ(TIM1_BRK_TIM15_IRQn);

  TIM_InitStruct.Prescaler = 31;
  TIM_InitStruct.CounterMode = LL_TIM_COUNTERMODE_UP;
  TIM_InitStruct.Autoreload = 4095;
  TIM_InitStruct.ClockDivision = LL_TIM_CLOCKDIVISION_DIV1;
  TIM_InitStruct.RepetitionCounter = 0;
  LL_TIM_Init(TIM1, &TIM_InitStruct);
  LL_TIM_EnableARRPreload(TIM1);
  LL_TIM_SetClockSource(TIM1, LL_TIM_CLOCKSOURCE_INTERNAL);
  LL_TIM_OC_EnablePreload(TIM1, LL_TIM_CHANNEL_CH4);
  TIM_OC_InitStruct.OCMode = LL_TIM_OCMODE_PWM1;
  TIM_OC_InitStruct.OCState = LL_TIM_OCSTATE_DISABLE;
  TIM_OC_InitStruct.OCNState = LL_TIM_OCSTATE_DISABLE;
  TIM_OC_InitStruct.CompareValue = 0;
  TIM_OC_InitStruct.OCPolarity = LL_TIM_OCPOLARITY_HIGH;
  TIM_OC_InitStruct.OCIdleState = LL_TIM_OCIDLESTATE_LOW;
  TIM_OC_InitStruct.OCNIdleState = LL_TIM_OCIDLESTATE_LOW;
  LL_TIM_OC_Init(TIM1, LL_TIM_CHANNEL_CH4, &TIM_OC_InitStruct);
  LL_TIM_OC_DisableFast(TIM1, LL_TIM_CHANNEL_CH4);
  LL_TIM_SetTriggerOutput(TIM1, LL_TIM_TRGO_RESET);
  LL_TIM_SetTriggerOutput2(TIM1, LL_TIM_TRGO2_RESET);
  LL_TIM_DisableMasterSlaveMode(TIM1);
  TIM_BDTRInitStruct.OSSRState = LL_TIM_OSSR_DISABLE;
  TIM_BDTRInitStruct.OSSIState = LL_TIM_OSSI_DISABLE;
  TIM_BDTRInitStruct.LockLevel = LL_TIM_LOCKLEVEL_OFF;
  TIM_BDTRInitStruct.DeadTime = 0;
  TIM_BDTRInitStruct.BreakState = LL_TIM_BREAK_DISABLE;
  TIM_BDTRInitStruct.BreakPolarity = LL_TIM_BREAK_POLARITY_HIGH;
  TIM_BDTRInitStruct.BreakFilter = LL_TIM_BREAK_FILTER_FDIV1;
  TIM_BDTRInitStruct.Break2State = LL_TIM_BREAK2_DISABLE;
  TIM_BDTRInitStruct.Break2Polarity = LL_TIM_BREAK2_POLARITY_HIGH;
  TIM_BDTRInitStruct.Break2Filter = LL_TIM_BREAK2_FILTER_FDIV1;
  TIM_BDTRInitStruct.AutomaticOutput = LL_TIM_AUTOMATICOUTPUT_DISABLE;
  LL_TIM_BDTR_Init(TIM1, &TIM_BDTRInitStruct);
  LL_AHB1_GRP1_EnableClock(LL_AHB1_GRP1_PERIPH_GPIOA);
  /**TIM1 GPIO Configuration
  PA11   ------> TIM1_CH4
  */
  GPIO_InitStruct.Pin = LL_GPIO_PIN_11;
  GPIO_InitStruct.Mode = LL_GPIO_MODE_ALTERNATE;
  GPIO_InitStruct.Speed = LL_GPIO_SPEED_FREQ_LOW;
  GPIO_InitStruct.OutputType = LL_GPIO_OUTPUT_PUSHPULL;
  GPIO_InitStruct.Pull = LL_GPIO_PULL_NO;
  GPIO_InitStruct.Alternate = LL_GPIO_AF_11;
  LL_GPIO_Init(GPIOA, &GPIO_InitStruct);

}

static void MX_TIM2_Init(void)
{

  LL_TIM_InitTypeDef TIM_InitStruct = {0};
  LL_TIM_OC_InitTypeDef TIM_OC_InitStruct = {0};

  LL_GPIO_InitTypeDef GPIO_InitStruct = {0};

  /* Peripheral clock enable */
  LL_APB1_GRP1_EnableClock(LL_APB1_GRP1_PERIPH_TIM2);

  TIM_InitStruct.Prescaler = 1920;
  TIM_InitStruct.CounterMode = LL_TIM_COUNTERMODE_UP;
  TIM_InitStruct.Autoreload = 255;
  TIM_InitStruct.ClockDivision = LL_TIM_CLOCKDIVISION_DIV1;
  LL_TIM_Init(TIM2, &TIM_InitStruct);
  LL_TIM_DisableARRPreload(TIM2);
  LL_TIM_SetClockSource(TIM2, LL_TIM_CLOCKSOURCE_INTERNAL);
  LL_TIM_OC_EnablePreload(TIM2, LL_TIM_CHANNEL_CH1);
  TIM_OC_InitStruct.OCMode = LL_TIM_OCMODE_PWM1;
  TIM_OC_InitStruct.OCState = LL_TIM_OCSTATE_DISABLE;
  TIM_OC_InitStruct.OCNState = LL_TIM_OCSTATE_DISABLE;
  TIM_OC_InitStruct.CompareValue = 0;
  TIM_OC_InitStruct.OCPolarity = LL_TIM_OCPOLARITY_HIGH;
  LL_TIM_OC_Init(TIM2, LL_TIM_CHANNEL_CH1, &TIM_OC_InitStruct);
  LL_TIM_OC_DisableFast(TIM2, LL_TIM_CHANNEL_CH1);
  LL_TIM_OC_EnablePreload(TIM2, LL_TIM_CHANNEL_CH2);
  LL_TIM_OC_Init(TIM2, LL_TIM_CHANNEL_CH2, &TIM_OC_InitStruct);
  LL_TIM_OC_DisableFast(TIM2, LL_TIM_CHANNEL_CH2);
  LL_TIM_OC_EnablePreload(TIM2, LL_TIM_CHANNEL_CH3);
  LL_TIM_OC_Init(TIM2, LL_TIM_CHANNEL_CH3, &TIM_OC_InitStruct);
  LL_TIM_OC_DisableFast(TIM2, LL_TIM_CHANNEL_CH3);
  LL_TIM_SetTriggerOutput(TIM2, LL_TIM_TRGO_RESET);
  LL_TIM_DisableMasterSlaveMode(TIM2);
  LL_AHB1_GRP1_EnableClock(LL_AHB1_GRP1_PERIPH_GPIOA);
  LL_AHB1_GRP1_EnableClock(LL_AHB1_GRP1_PERIPH_GPIOB);
  /**TIM2 GPIO Configuration
  PA1   ------> TIM2_CH2
  PB10   ------> TIM2_CH3
  PA15   ------> TIM2_CH1
  */
  GPIO_InitStruct.Pin = LL_GPIO_PIN_1|LL_GPIO_PIN_15;
  GPIO_InitStruct.Mode = LL_GPIO_MODE_ALTERNATE;
  GPIO_InitStruct.Speed = LL_GPIO_SPEED_FREQ_LOW;
  GPIO_InitStruct.OutputType = LL_GPIO_OUTPUT_PUSHPULL;
  GPIO_InitStruct.Pull = LL_GPIO_PULL_NO;
  GPIO_InitStruct.Alternate = LL_GPIO_AF_1;
  LL_GPIO_Init(GPIOA, &GPIO_InitStruct);

  GPIO_InitStruct.Pin = LL_GPIO_PIN_10;
  GPIO_InitStruct.Mode = LL_GPIO_MODE_ALTERNATE;
  GPIO_InitStruct.Speed = LL_GPIO_SPEED_FREQ_LOW;
  GPIO_InitStruct.OutputType = LL_GPIO_OUTPUT_PUSHPULL;
  GPIO_InitStruct.Pull = LL_GPIO_PULL_NO;
  GPIO_InitStruct.Alternate = LL_GPIO_AF_1;
  LL_GPIO_Init(GPIOB, &GPIO_InitStruct);

}

static void MX_TIM3_Init(void)
{

  LL_TIM_InitTypeDef TIM_InitStruct = {0};

  /* Peripheral clock enable */
  LL_APB1_GRP1_EnableClock(LL_APB1_GRP1_PERIPH_TIM3);

  TIM_InitStruct.Prescaler = 0;
  TIM_InitStruct.CounterMode = LL_TIM_COUNTERMODE_UP;
  TIM_InitStruct.Autoreload = 65535;
  TIM_InitStruct.ClockDivision = LL_TIM_CLOCKDIVISION_DIV1;
  LL_TIM_Init(TIM3, &TIM_InitStruct);
  LL_TIM_DisableARRPreload(TIM3);
  LL_TIM_SetClockSource(TIM3, LL_TIM_CLOCKSOURCE_INTERNAL);
  LL_TIM_SetTriggerOutput(TIM3, LL_TIM_TRGO_RESET);
  LL_TIM_DisableMasterSlaveMode(TIM3);

}

static void MX_TIM6_Init(void)
{

  LL_TIM_InitTypeDef TIM_InitStruct = {0};

  /* Peripheral clock enable */
  LL_APB1_GRP1_EnableClock(LL_APB1_GRP1_PERIPH_TIM6);

  TIM_InitStruct.Prescaler = 0;
  TIM_InitStruct.CounterMode = LL_TIM_COUNTERMODE_UP;
  TIM_InitStruct.Autoreload = 49;
  LL_TIM_Init(TIM6, &TIM_InitStruct);
  LL_TIM_DisableARRPreload(TIM6);
  LL_TIM_SetTriggerOutput(TIM6, LL_TIM_TRGO_UPDATE);
  LL_TIM_DisableMasterSlaveMode(TIM6);

}

static void MX_TIM15_Init(void)
{

  LL_TIM_InitTypeDef TIM_InitStruct = {0};

  LL_GPIO_InitTypeDef GPIO_InitStruct = {0};

  /* Peripheral clock enable */
  LL_APB2_GRP1_EnableClock(LL_APB2_GRP1_PERIPH_TIM15);

  LL_AHB1_GRP1_EnableClock(LL_AHB1_GRP1_PERIPH_GPIOB);
  /**TIM15 GPIO Configuration
  PB14   ------> TIM15_CH1
  */
  GPIO_InitStruct.Pin = LL_GPIO_PIN_14;
  GPIO_InitStruct.Mode = LL_GPIO_MODE_ALTERNATE;
  GPIO_InitStruct.Speed = LL_GPIO_SPEED_FREQ_LOW;
  GPIO_InitStruct.OutputType = LL_GPIO_OUTPUT_PUSHPULL;
  GPIO_InitStruct.Pull = LL_GPIO_PULL_UP;
  GPIO_InitStruct.Alternate = LL_GPIO_AF_1;
  LL_GPIO_Init(GPIOB, &GPIO_InitStruct);

  /* TIM15 interrupt Init */
  NVIC_SetPriority(TIM1_BRK_TIM15_IRQn, NVIC_EncodePriority(NVIC_GetPriorityGrouping(),0, 0));
  NVIC_EnableIRQ(TIM1_BRK_TIM15_IRQn);

  TIM_InitStruct.Prescaler = 244;
  TIM_InitStruct.CounterMode = LL_TIM_COUNTERMODE_UP;
  TIM_InitStruct.Autoreload = 65535;
  TIM_InitStruct.ClockDivision = LL_TIM_CLOCKDIVISION_DIV1;
  TIM_InitStruct.RepetitionCounter = 0;
  LL_TIM_Init(TIM15, &TIM_InitStruct);
  LL_TIM_DisableARRPreload(TIM15);
  LL_TIM_SetClockSource(TIM15, LL_TIM_CLOCKSOURCE_INTERNAL);
  LL_TIM_SetTriggerOutput(TIM15, LL_TIM_TRGO_RESET);
  LL_TIM_DisableMasterSlaveMode(TIM15);
  LL_TIM_IC_SetActiveInput(TIM15, LL_TIM_CHANNEL_CH1, LL_TIM_ACTIVEINPUT_DIRECTTI);
  LL_TIM_IC_SetPrescaler(TIM15, LL_TIM_CHANNEL_CH1, LL_TIM_ICPSC_DIV1);
  LL_TIM_IC_SetFilter(TIM15, LL_TIM_CHANNEL_CH1, LL_TIM_IC_FILTER_FDIV32_N8);
  LL_TIM_IC_SetPolarity(TIM15, LL_TIM_CHANNEL_CH1, LL_TIM_IC_POLARITY_RISING);

}

static void MX_TIM17_Init(void)
{

  LL_TIM_InitTypeDef TIM_InitStruct = {0};
  LL_TIM_OC_InitTypeDef TIM_OC_InitStruct = {0};
  LL_TIM_BDTR_InitTypeDef TIM_BDTRInitStruct = {0};

  LL_GPIO_InitTypeDef GPIO_InitStruct = {0};

  /* Peripheral clock enable */
  LL_APB2_GRP1_EnableClock(LL_APB2_GRP1_PERIPH_TIM17);

  TIM_InitStruct.Prescaler = 976;
  TIM_InitStruct.CounterMode = LL_TIM_COUNTERMODE_UP;
  TIM_InitStruct.Autoreload = 65535;
  TIM_InitStruct.ClockDivision = LL_TIM_CLOCKDIVISION_DIV1;
  TIM_InitStruct.RepetitionCounter = 0;
  LL_TIM_Init(TIM17, &TIM_InitStruct);
  LL_TIM_DisableARRPreload(TIM17);
  LL_TIM_OC_EnablePreload(TIM17, LL_TIM_CHANNEL_CH1);
  TIM_OC_InitStruct.OCMode = LL_TIM_OCMODE_PWM1;
  TIM_OC_InitStruct.OCState = LL_TIM_OCSTATE_DISABLE;
  TIM_OC_InitStruct.OCNState = LL_TIM_OCSTATE_DISABLE;
  TIM_OC_InitStruct.CompareValue = 10000;
  TIM_OC_InitStruct.OCPolarity = LL_TIM_OCPOLARITY_HIGH;
  TIM_OC_InitStruct.OCNPolarity = LL_TIM_OCPOLARITY_HIGH;
  TIM_OC_InitStruct.OCIdleState = LL_TIM_OCIDLESTATE_LOW;
  TIM_OC_InitStruct.OCNIdleState = LL_TIM_OCIDLESTATE_LOW;
  LL_TIM_OC_Init(TIM17, LL_TIM_CHANNEL_CH1, &TIM_OC_InitStruct);
  LL_TIM_OC_DisableFast(TIM17, LL_TIM_CHANNEL_CH1);
  TIM_BDTRInitStruct.OSSRState = LL_TIM_OSSR_DISABLE;
  TIM_BDTRInitStruct.OSSIState = LL_TIM_OSSI_DISABLE;
  TIM_BDTRInitStruct.LockLevel = LL_TIM_LOCKLEVEL_OFF;
  TIM_BDTRInitStruct.DeadTime = 0;
  TIM_BDTRInitStruct.BreakState = LL_TIM_BREAK_DISABLE;
  TIM_BDTRInitStruct.BreakPolarity = LL_TIM_BREAK_POLARITY_HIGH;
  TIM_BDTRInitStruct.BreakFilter = LL_TIM_BREAK_FILTER_FDIV1;
  TIM_BDTRInitStruct.AutomaticOutput = LL_TIM_AUTOMATICOUTPUT_DISABLE;
  LL_TIM_BDTR_Init(TIM17, &TIM_BDTRInitStruct);
  LL_AHB1_GRP1_EnableClock(LL_AHB1_GRP1_PERIPH_GPIOA);
  /**TIM17 GPIO Configuration
  PA7   ------> TIM17_CH1
  */
  GPIO_InitStruct.Pin = LL_GPIO_PIN_7;
  GPIO_InitStruct.Mode = LL_GPIO_MODE_ALTERNATE;
  GPIO_InitStruct.Speed = LL_GPIO_SPEED_FREQ_LOW;
  GPIO_InitStruct.OutputType = LL_GPIO_OUTPUT_PUSHPULL;
  GPIO_InitStruct.Pull = LL_GPIO_PULL_NO;
  GPIO_InitStruct.Alternate = LL_GPIO_AF_1;
  LL_GPIO_Init(GPIOA, &GPIO_InitStruct);

}

static void MX_USART2_UART_Init(void)
{

  LL_USART_InitTypeDef USART_InitStruct = {0};

  LL_GPIO_InitTypeDef GPIO_InitStruct = {0};

  /* Peripheral clock enable */
  LL_APB1_GRP1_EnableClock(LL_APB1_GRP1_PERIPH_USART2);

  LL_AHB1_GRP1_EnableClock(LL_AHB1_GRP1_PERIPH_GPIOA);
  /**USART2 GPIO Configuration
  PA2   ------> USART2_TX
  PA3   ------> USART2_RX
  */
  GPIO_InitStruct.Pin = USART_TX_Pin|USART_RX_Pin;
  GPIO_InitStruct.Mode = LL_GPIO_MODE_ALTERNATE;
  GPIO_InitStruct.Speed = LL_GPIO_SPEED_FREQ_HIGH;
  GPIO_InitStruct.OutputType = LL_GPIO_OUTPUT_PUSHPULL;
  GPIO_InitStruct.Pull = LL_GPIO_PULL_NO;
  GPIO_InitStruct.Alternate = LL_GPIO_AF_7;
  LL_GPIO_Init(GPIOA, &GPIO_InitStruct);

  /* USART2 DMA Init */

  /* USART2_RX Init */
  LL_DMA_SetDataTransferDirection(DMA1, LL_DMA_CHANNEL_6, LL_DMA_DIRECTION_PERIPH_TO_MEMORY);

  LL_DMA_SetChannelPriorityLevel(DMA1, LL_DMA_CHANNEL_6, LL_DMA_PRIORITY_LOW);

  LL_DMA_SetMode(DMA1, LL_DMA_CHANNEL_6, LL_DMA_MODE_CIRCULAR);

  LL_DMA_SetPeriphIncMode(DMA1, LL_DMA_CHANNEL_6, LL_DMA_PERIPH_NOINCREMENT);

  LL_DMA_SetMemoryIncMode(DMA1, LL_DMA_CHANNEL_6, LL_DMA_MEMORY_INCREMENT);

  LL_DMA_SetPeriphSize(DMA1, LL_DMA_CHANNEL_6, LL_DMA_PDATAALIGN_BYTE);

  LL_DMA_SetMemorySize(DMA1, LL_DMA_CHANNEL_6, LL_DMA_MDATAALIGN_BYTE);

  /* USART2 interrupt Init */
  NVIC_SetPriority(USART2_IRQn, NVIC_EncodePriority(NVIC_GetPriorityGrouping(),0, 0));
  NVIC_EnableIRQ(USART2_IRQn);

  USART_InitStruct.BaudRate = 115200;
  USART_InitStruct.DataWidth = LL_USART_DATAWIDTH_8B;
  USART_InitStruct.StopBits = LL_USART_STOPBITS_1;
  USART_InitStruct.Parity = LL_USART_PARITY_NONE;
  USART_InitStruct.TransferDirection = LL_USART_DIRECTION_TX_RX;
  USART_InitStruct.HardwareFlowControl = LL_USART_HWCONTROL_NONE;
  USART_InitStruct.OverSampling = LL_USART_OVERSAMPLING_16;
  LL_USART_Init(USART2, &USART_InitStruct);
  LL_USART_DisableIT_CTS(USART2);
  LL_USART_ConfigAsyncMode(USART2);
  LL_USART_Enable(USART2);

}

static void MX_DMA_Init(void)
{

  /* Init with LL driver */
  /* DMA controller clock enable */
  LL_AHB1_GRP1_EnableClock(LL_AHB1_GRP1_PERIPH_DMA1);

  /* DMA interrupt init */
  /* DMA1_Channel1_IRQn interrupt configuration */
  NVIC_SetPriority(DMA1_Channel1_IRQn, NVIC_EncodePriority(NVIC_GetPriorityGrouping(),0, 0));
  NVIC_EnableIRQ(DMA1_Channel1_IRQn);
  /* DMA1_Channel2_IRQn interrupt configuration */
  NVIC_SetPriority(DMA1_Channel2_IRQn, NVIC_EncodePriority(NVIC_GetPriorityGrouping(),0, 0));
  NVIC_EnableIRQ(DMA1_Channel2_IRQn);
  /* DMA1_Channel3_IRQn interrupt configuration */
  NVIC_SetPriority(DMA1_Channel3_IRQn, NVIC_EncodePriority(NVIC_GetPriorityGrouping(),0, 0));
  NVIC_EnableIRQ(DMA1_Channel3_IRQn);
  /* DMA1_Channel4_IRQn interrupt configuration */
  NVIC_SetPriority(DMA1_Channel4_IRQn, NVIC_EncodePriority(NVIC_GetPriorityGrouping(),0, 0));
  NVIC_EnableIRQ(DMA1_Channel4_IRQn);
  /* DMA1_Channel6_IRQn interrupt configuration */
  NVIC_SetPriority(DMA1_Channel6_IRQn, NVIC_EncodePriority(NVIC_GetPriorityGrouping(),0, 0));
  NVIC_EnableIRQ(DMA1_Channel6_IRQn);

}

static void MX_GPIO_Init(void)
{
  LL_EXTI_InitTypeDef EXTI_InitStruct = {0};
  LL_GPIO_InitTypeDef GPIO_InitStruct = {0};

  /* GPIO Ports Clock Enable */
  LL_AHB1_GRP1_EnableClock(LL_AHB1_GRP1_PERIPH_GPIOC);
  LL_AHB1_GRP1_EnableClock(LL_AHB1_GRP1_PERIPH_GPIOF);
  LL_AHB1_GRP1_EnableClock(LL_AHB1_GRP1_PERIPH_GPIOA);
  LL_AHB1_GRP1_EnableClock(LL_AHB1_GRP1_PERIPH_GPIOB);

  /**/
  LL_GPIO_ResetOutputPin(GPIOC, LL_GPIO_PIN_6|LL_GPIO_PIN_7|LL_GPIO_PIN_8|LL_GPIO_PIN_9);

  /**/
  LL_GPIO_ResetOutputPin(GPIOA, LL_GPIO_PIN_8);

  /**/
  LL_SYSCFG_SetEXTISource(LL_SYSCFG_EXTI_PORTC, LL_SYSCFG_EXTI_LINE13);

  /**/
  LL_GPIO_SetPinPull(B1_GPIO_Port, B1_Pin, LL_GPIO_PULL_NO);

  /**/
  LL_GPIO_SetPinMode(B1_GPIO_Port, B1_Pin, LL_GPIO_MODE_INPUT);

  /**/
  EXTI_InitStruct.Line_0_31 = LL_EXTI_LINE_13;
  EXTI_InitStruct.Line_32_63 = LL_EXTI_LINE_NONE;
  EXTI_InitStruct.LineCommand = ENABLE;
  EXTI_InitStruct.Mode = LL_EXTI_MODE_IT;
  EXTI_InitStruct.Trigger = LL_EXTI_TRIGGER_FALLING;
  LL_EXTI_Init(&EXTI_InitStruct);

  /**/
  GPIO_InitStruct.Pin = LL_GPIO_PIN_6|LL_GPIO_PIN_7|LL_GPIO_PIN_8|LL_GPIO_PIN_9;
  GPIO_InitStruct.Mode = LL_GPIO_MODE_OUTPUT;
  GPIO_InitStruct.Speed = LL_GPIO_SPEED_FREQ_LOW;
  GPIO_InitStruct.OutputType = LL_GPIO_OUTPUT_PUSHPULL;
  GPIO_InitStruct.Pull = LL_GPIO_PULL_NO;
  LL_GPIO_Init(GPIOC, &GPIO_InitStruct);

  /**/
  GPIO_InitStruct.Pin = LL_GPIO_PIN_8;
  GPIO_InitStruct.Mode = LL_GPIO_MODE_OUTPUT;
  GPIO_InitStruct.Speed = LL_GPIO_SPEED_FREQ_LOW;
  GPIO_InitStruct.OutputType = LL_GPIO_OUTPUT_PUSHPULL;
  GPIO_InitStruct.Pull = LL_GPIO_PULL_NO;
  LL_GPIO_Init(GPIOA, &GPIO_InitStruct);

  /**/
  GPIO_InitStruct.Pin = LL_GPIO_PIN_12;
  GPIO_InitStruct.Mode = LL_GPIO_MODE_INPUT;
  GPIO_InitStruct.Pull = LL_GPIO_PULL_NO;
  LL_GPIO_Init(GPIOC, &GPIO_InitStruct);

  /**/
  GPIO_InitStruct.Pin = LL_GPIO_PIN_4|LL_GPIO_PIN_5|LL_GPIO_PIN_6|LL_GPIO_PIN_8
                          |LL_GPIO_PIN_9;
  GPIO_InitStruct.Mode = LL_GPIO_MODE_INPUT;
  GPIO_InitStruct.Pull = LL_GPIO_PULL_NO;
  LL_GPIO_Init(GPIOB, &GPIO_InitStruct);

}

void HAL_TIM_PeriodElapsedCallback(TIM_HandleTypeDef *htim)
{
  if (htim->Instance == TIM7) {
    HAL_IncTick();
  }
}

void Error_Handler(void)
{
  __disable_irq();
  while (1)
  {
  }
}
